# AT32F425xx_v2 register map
Vendor: Keil; Series: AT32F425; File version: 1.0
CPU: CM4 r0p1, little endian, no MPU, FPU, 4 interrupt priority bits
Registers are 32-bit, read-write, reset 0x0 unless marked. A register's access mark holds for its fields unless they carry their own. Offsets are from the block's base; [hi:lo] are bit positions.

## CRM — Clock and reset management
Base 0x40021000
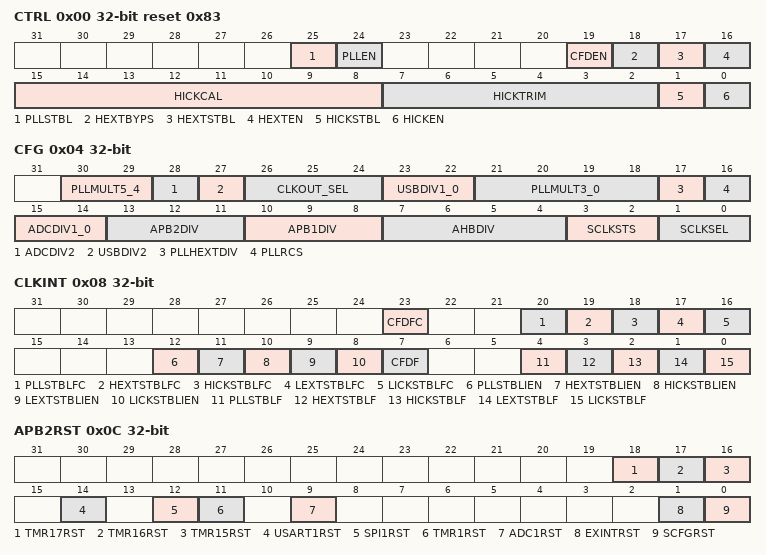
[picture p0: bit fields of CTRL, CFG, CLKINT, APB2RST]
0x00 CTRL reset 0x83 — Clock control register
  [25] PLLSTBL ro — PLL clock ready flag
  [24] PLLEN — PLL enable
  [19] CFDEN — Clock failure detection enable
  [18] HEXTBYPS — High speed exernal crystal bypass
  [17] HEXTSTBL ro — High speed exernal crystal ready flag
  [16] HEXTEN — High speed exernal crystal enable
  [15:8] HICKCAL ro — High speed internal clock calibration
  [7:2] HICKTRIM — High speed internal clock trimming
  [1] HICKSTBL ro — High speed internal clock ready flag
  [0] HICKEN — High speed internal clock enable
0x04 CFG — Clock configuration register (CRM_CFG)
  [30:29] PLLMULT5_4 — PLL Multiplication Factor bit5 and bit4
  [28] ADCDIV2 — ADC division bit2
  [27] USBDIV2 — USB division bit2
  [26:24] CLKOUT_SEL — Clock output selection bit2 to bit0
  [23:22] USBDIV1_0 — USB division bit1 and bit0
  [21:18] PLLMULT3_0 — PLL Multiplication Factor bit3 to bit0
  [17] PLLHEXTDIV — HEXT division selection for PLL entry clock
  [16] PLLRCS — PLL reference clock select
  [15:14] ADCDIV1_0 — ADC division bit1 and bit0
  [13:11] APB2DIV — APB2 division
  [10:8] APB1DIV — APB1 division
  [7:4] AHBDIV — AHB division
  [3:2] SCLKSTS ro — System Clock select Status
  [1:0] SCLKSEL — System clock select
0x08 CLKINT — Clock interrupt register (CRM_CLKINT)
  [23] CFDFC wo — Clock failure detection interrupt clear
  [20] PLLSTBLFC wo — PLL ready interrupt clear
  [19] HEXTSTBLFC wo — HEXT ready interrupt clear
  [18] HICKSTBLFC wo — HICK ready interrupt clear
  [17] LEXTSTBLFC wo — LEXT ready interrupt clear
  [16] LICKSTBLFC wo — LICK ready interrupt clear
  [12] PLLSTBLIEN — PLL ready interrupt enable
  [11] HEXTSTBLIEN — HEXT ready interrupt enable
  [10] HICKSTBLIEN — HICK ready interrupt enable
  [9] LEXTSTBLIEN — LEXT ready interrupt enable
  [8] LICKSTBLIEN — LICK ready interrupt enable
  [7] CFDF ro — Clock failure detection interrupt flag
  [4] PLLSTBLF ro — PLL ready interrupt flag
  [3] HEXTSTBLF ro — HEXT ready interrupt flag
  [2] HICKSTBLF ro — HICK ready interrupt flag
  [1] LEXTSTBLF ro — LEXT ready interrupt flag
  [0] LICKSTBLF ro — LICK ready interrupt flag
0x0C APB2RST — APB2 peripheral reset register (CRM_APB2RST)
  [18] TMR17RST — Timer17 reset
  [17] TMR16RST — Timer16 reset
  [16] TMR15RST — Timer15 reset
  [14] USART1RST — USART1 reset
  [12] SPI1RST — SPI1 reset
  [11] TMR1RST — TMR1 reset
  [9] ADC1RST — ADC1 reset
  [1] EXINTRST — External interrupt reset
  [0] SCFGRST — System config reset
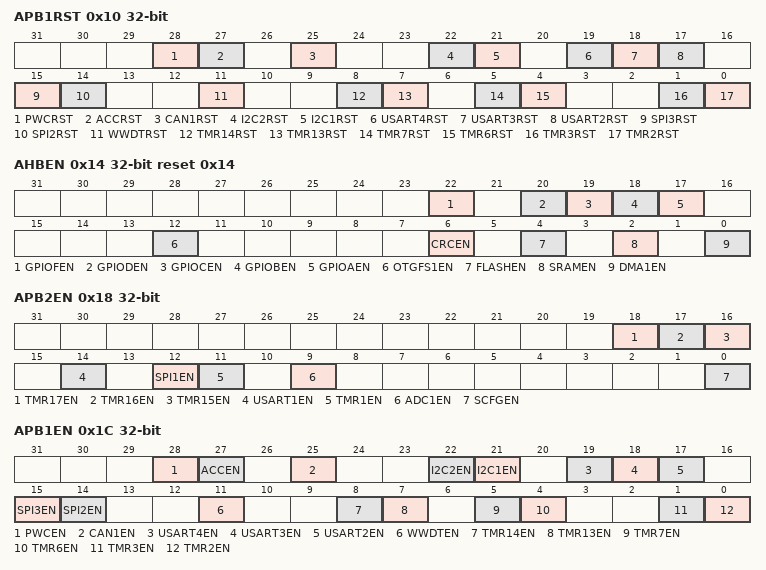
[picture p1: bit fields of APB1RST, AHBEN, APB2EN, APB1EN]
0x10 APB1RST — APB1 peripheral reset register (CRM_APB1RST)
  [28] PWCRST — Power controller reset
  [27] ACCRST — ACC reset
  [25] CAN1RST — CAN1 reset
  [22] I2C2RST — I2C2 reset
  [21] I2C1RST — I2C1 reset
  [19] USART4RST — USART 4 reset
  [18] USART3RST — USART 3 reset
  [17] USART2RST — USART 2 reset
  [15] SPI3RST — SPI3 reset
  [14] SPI2RST — SPI2 reset
  [11] WWDTRST — Window watchdog timer reset
  [8] TMR14RST — Timer 14 reset
  [7] TMR13RST — Timer 13 reset
  [5] TMR7RST — Timer 7 reset
  [4] TMR6RST — Timer 6 reset
  [1] TMR3RST — Timer 3 reset
  [0] TMR2RST — Timer 2 reset
0x14 AHBEN reset 0x14 — AHB Peripheral Clock enable register (CRM_AHBEN)
  [22] GPIOFEN — I/O port F clock enable
  [20] GPIODEN — I/O port D clock enable
  [19] GPIOCEN — I/O port C clock enable
  [18] GPIOBEN — I/O port B clock enable
  [17] GPIOAEN — I/O port A clock enable
  [12] OTGFS1EN — OTGFS1 clock enable
  [6] CRCEN — CRC clock enable
  [4] FLASHEN — FLASH clock enable
  [2] SRAMEN — SRAM interface clock enable
  [0] DMA1EN — DMA1 clock enable
0x18 APB2EN — APB2 peripheral clock enable register (CRM_APB2EN)
  [18] TMR17EN — Timer17 clock enable
  [17] TMR16EN — Timer16 clock enable
  [16] TMR15EN — Timer15 clock enable
  [14] USART1EN — USART1 clock enable
  [12] SPI1EN — SPI1 clock enable
  [11] TMR1EN — Timer1 clock enable
  [9] ADC1EN — ADC1 clock enable
  [0] SCFGEN — System config clock enable
0x1C APB1EN — APB1 peripheral clock enable register (CRM_APB1EN)
  [28] PWCEN — Power clock enable
  [27] ACCEN — ACC clock enable
  [25] CAN1EN — CAN1 clock enable
  [22] I2C2EN — I2C2 clock enable
  [21] I2C1EN — I2C1 clock enable
  [19] USART4EN — USART4 clock enable
  [18] USART3EN — USART3 clock enable
  [17] USART2EN — USART2 clock enable
  [15] SPI3EN — SPI3 clock enable
  [14] SPI2EN — SPI2 clock enable
  [11] WWDTEN — Window watchdog timer clock enable
  [8] TMR14EN — Timer14 clock enable
  [7] TMR13EN — Timer13 clock enable
  [5] TMR7EN — Timer7 clock enable
  [4] TMR6EN — Timer6 clock enable
  [1] TMR3EN — Timer3 clock enable
  [0] TMR2EN — Timer2 clock enable
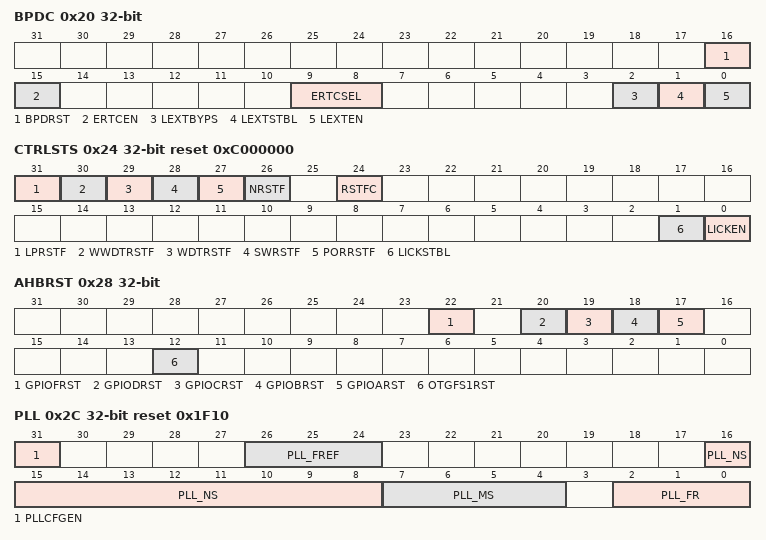
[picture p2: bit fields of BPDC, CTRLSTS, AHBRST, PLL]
0x20 BPDC — Battery powered domain control register (CRM_BPDC)
  [16] BPDRST — Battery powered domain software reset
  [15] ERTCEN — ERTC clock enable
  [9:8] ERTCSEL — ERTC clock selection
  [2] LEXTBYPS — Low speed external crystal bypass
  [1] LEXTSTBL ro — Low speed external crystal ready
  [0] LEXTEN — Low speed external crystal enable
0x24 CTRLSTS reset 0xC000000 — Control/status register (CRM_CTRLSTS)
  [31] LPRSTF — Low-power reset flag
  [30] WWDTRSTF — Window watchdog timer reset flag
  [29] WDTRSTF — Watchdog timer reset flag
  [28] SWRSTF — Software reset flag
  [27] PORRSTF — POR/LVR reset flag
  [26] NRSTF — PIN reset flag
  [24] RSTFC — Reset flag clear
  [1] LICKSTBL ro — Low speed internal clock ready
  [0] LICKEN — Low speed internal clock enable
0x28 AHBRST — AHB reset register
  [22] GPIOFRST — IO port F reset
  [20] GPIODRST — IO port D reset
  [19] GPIOCRST — IO port C reset
  [18] GPIOBRST — IO port B reset
  [17] GPIOARST — IO port A reset
  [12] OTGFS1RST — OTGFS1 reset
0x2C PLL reset 0x1F10 — PLL configuration register (CRM_PLL)
  [31] PLLCFGEN — PLL config enable
  [26:24] PLL_FREF — PLL entry clock reference frequency
  [16:8] PLL_NS
  [7:4] PLL_MS
  [2:0] PLL_FR
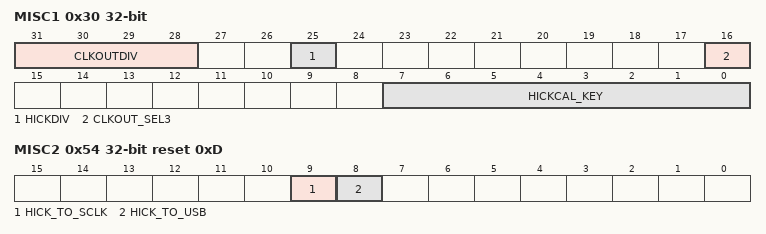
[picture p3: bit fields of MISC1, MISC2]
0x30 MISC1 — Miscellaneous register1
  [31:28] CLKOUTDIV — Clock output division
  [25] HICKDIV — HICK 6 divider selection
  [16] CLKOUT_SEL3 — Clock output bit3
  [7:0] HICKCAL_KEY — HICKCAL write key value
0x54 MISC2 reset 0xD — Miscellaneous register2
  [9] HICK_TO_SCLK — HICK to system clock
  [8] HICK_TO_USB

## Notices in the file
Copyright (C) 2012-2014 ARM Limited. All rights reserved.
Purpose: System Viewer Description (SVD) Example (Schema Version 1.1)
This is a description of a none-existent and incomplete device
for demonstration purposes only.
Redistribution and use in source and binary forms, with or without
modification, are permitted provided that the following conditions are met:
- Redistributions of source code must retain the above copyright
notice, this list of conditions and the following disclaimer.
- Redistributions in binary form must reproduce the above copyright
notice, this list of conditions and the following disclaimer in the
documentation and/or other materials provided with the distribution.
- Neither the name of ARM nor the names of its contributors may be used
to endorse or promote products derived from this software without
specific prior written permission.
THIS SOFTWARE IS PROVIDED BY THE COPYRIGHT HOLDERS AND CONTRIBUTORS "AS IS"
AND ANY EXPRESS OR IMPLIED WARRANTIES, INCLUDING, BUT NOT LIMITED TO, THE
IMPLIED WARRANTIES OF MERCHANTABILITY AND FITNESS FOR A PARTICULAR PURPOSE
ARE DISCLAIMED. IN NO EVENT SHALL COPYRIGHT HOLDERS AND CONTRIBUTORS BE
LIABLE FOR ANY DIRECT, INDIRECT, INCIDENTAL, SPECIAL, EXEMPLARY, OR
CONSEQUENTIAL DAMAGES (INCLUDING, BUT NOT LIMITED TO, PROCUREMENT OF
SUBSTITUTE GOODS OR SERVICES; LOSS OF USE, DATA, OR PROFITS; OR BUSINESS
INTERRUPTION) HOWEVER CAUSED AND ON ANY THEORY OF LIABILITY, WHETHER IN
CONTRACT, STRICT LIABILITY, OR TORT (INCLUDING NEGLIGENCE OR OTHERWISE)
ARISING IN ANY WAY OUT OF THE USE OF THIS SOFTWARE, EVEN IF ADVISED OF THE
POSSIBILITY OF SUCH DAMAGE.
